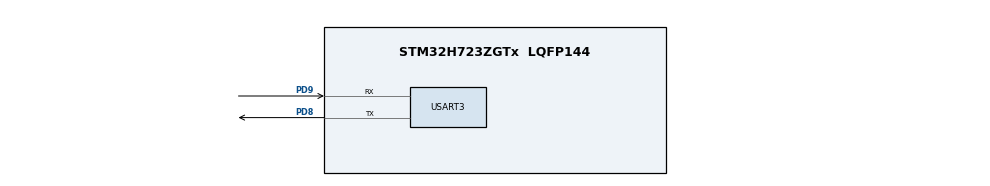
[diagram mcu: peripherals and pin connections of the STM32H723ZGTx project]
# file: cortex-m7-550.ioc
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Mcu.Family=STM32H7
VP_STMicroelectronics.X-CUBE-AI_VS_ArtificialOoIntelligenceJjXAaCUBEAaAI_6.0.0.Mode=ArtificialOoIntelligenceJjXAaCUBEAaAI
RCC.CortexFreq_Value=550000000
STMicroelectronics.X-CUBE-AI.6.0.0.MaximumSizeOfInputLayer=AI_NETWORK_IN_1_SIZE_BYTES
RCC.HPRE=RCC_HCLK_DIV2
RCC.PLLFRACN=3072
PA13(JTMS/SWDIO).Signal=DEBUG_JTMS-SWDIO
RCC.PLL2FRACN=0
STMicroelectronics.X-CUBE-AI.6.0.0.StackSize=0x1000
PD8.GPIO_PuPd=GPIO_PULLUP
PD9.Mode=Asynchronous
RCC.SYSCLKSource=RCC_SYSCLKSOURCE_PLLCLK
ProjectManager.StackSize=0x1000
PA13(JTMS/SWDIO).Mode=Trace_Asynchronous_SW
USART3.VirtualMode-Asynchronous=VM_ASYNC
STMicroelectronics.X-CUBE-AI.6.0.0.ModelType-336dc0c4d0ba22692615627b5872e3af75208939208f4fb2798e3d2edae12cc2=Saved model
RCC.HCLKFreq_Value=275000000
PD8.Signal=USART3_TX
STMicroelectronics.X-CUBE-AI.6.0.0.ModelStructureFile-336dc0c4d0ba22692615627b5872e3af75208939208f4fb2798e3d2edae12cc2=/Users/dominikpiorkowski/Desktop/drive/projekty/ML models/predict house price/predict_house_price.h5
RCC.DIVM1=4
STMicroelectronics.X-CUBE-AI.6.0.0.ModelMacc-336dc0c4d0ba22692615627b5872e3af75208939208f4fb2798e3d2edae12cc2=6771
STMicroelectronics.X-CUBE-AI.6.0.0.XAaCUBEAaAICcArtificialOoIntelligenceJjCore=true
PB3(JTDO/TRACESWO).Signal=DEBUG_JTDO-SWO
RCC.APB3Freq_Value=137500000
Mcu.Package=LQFP144
RCC.PLL3FRACN=0
RCC.D1PPRE=RCC_APB3_DIV2
PB3(JTDO/TRACESWO).Mode=Trace_Asynchronous_SW
STMicroelectronics.X-CUBE-AI.6.0.0.LatestDirectoryUsed-336dc0c4d0ba22692615627b5872e3af75208939208f4fb2798e3d2edae12cc2=/Users/dominikpiorkowski/Desktop/drive/projekty/ML models/predict house price
STMicroelectronics.X-CUBE-AI.6.0.0.ModelCompression-336dc0c4d0ba22692615627b5872e3af75208939208f4fb2798e3d2edae12cc2=1
RCC.APB4Freq_Value=137500000
TIM16.AutoReloadPreload=TIM_AUTORELOAD_PRELOAD_ENABLE
TIM16.Prescaler=9000-1
PD9.GPIO_PuPd=GPIO_PULLUP
STMicroelectronics.X-CUBE-AI.6.0.0.ModelKind-336dc0c4d0ba22692615627b5872e3af75208939208f4fb2798e3d2edae12cc2=KERAS
CORTEX_M7.CPU_ICache=Enabled
STMicroelectronics.X-CUBE-AI.6.0.0.MaximumSizeOfOutputLayer=AI_NETWORK_OUT_1_SIZE_BYTES
RCC.D2PPRE2=RCC_APB2_DIV2
RCC.D2PPRE1=RCC_APB1_DIV2
PD9.Signal=USART3_RX
VP_TIM16_VS_ClockSourceINT.Mode=Enable_Timer
RCC.DIVP1=1
NVIC.TIM16_IRQn=true\:0\:0\:false\:false\:true\:true\:true
STMicroelectronics.X-CUBE-AI.6.0.0.ModelHashList=336dc0c4d0ba22692615627b5872e3af75208939208f4fb2798e3d2edae12cc2
ProjectManager.TargetToolchain=STM32CubeIDE
STMicroelectronics.X-CUBE-AI.6.0.0.InternalRamActivationBufferMaxSize=AI_NETWORK_DATA_ACTIVATIONS_SIZE
RCC.DIVN1=34
STMicroelectronics.X-CUBE-AI.6.0.0.WorkingBufferStartAddrList=0xFFFFFFFF
STMicroelectronics.X-CUBE-AI.6.0.0.ModelNameList=network
RCC.USBFreq_Value=275000000
STMicroelectronics.X-CUBE-AI.6.0.0.MaximumNumberOfOutputLayer=1
PD8.Mode=Asynchronous
board=custom
TIM16.Period=10000-1
RCC.APB2Freq_Value=137500000
RCC.ADCFreq_Value=129000000
STMicroelectronics.X-CUBE-AI.6.0.0.ModelName-336dc0c4d0ba22692615627b5872e3af75208939208f4fb2798e3d2edae12cc2=network
STMicroelectronics.X-CUBE-AI.6.0.0.ModelRamOccupation-336dc0c4d0ba22692615627b5872e3af75208939208f4fb2798e3d2edae12cc2=384
PA14(JTCK/SWCLK).Mode=Trace_Asynchronous_SW
Mcu.Name=STM32H723ZGTx
RCC.SYSCLKFreq_VALUE=550000000
STMicroelectronics.X-CUBE-AI.6.0.0.ModelActualCompression-336dc0c4d0ba22692615627b5872e3af75208939208f4fb2798e3d2edae12cc2=0.0
STMicroelectronics.X-CUBE-AI.6.0.0.MaximumNumberOfInputLayer=1
ProjectManager.HeapSize=0x200
STMicroelectronics.X-CUBE-AI.6.0.0.HeapSize=0x200
NVIC.PriorityGroup=NVIC_PRIORITYGROUP_4
RCC.D3PPRE=RCC_APB4_DIV2
PA14(JTCK/SWCLK).Signal=DEBUG_JTCK-SWCLK
CORTEX_M7.CPU_DCache=Enabled
RCC.APB1Freq_Value=137500000
VP_CRC_VS_CRC.Mode=CRC_Activate
STMicroelectronics.X-CUBE-AI.6.0.0.ActivationBufferSizeList=384
STMicroelectronics.X-CUBE-AI.6.0.0.ModelFlashOccupation-336dc0c4d0ba22692615627b5872e3af75208939208f4fb2798e3d2edae12cc2=26136

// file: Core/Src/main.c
/* USER CODE BEGIN Header */
/**
  ******************************************************************************
  * @file           : main.c
  * @brief          : Main program body
  ******************************************************************************
  * @attention
  *
  * Copyright (c)	2021 STMicroelectronics,
  * 				2021 Dominik Piórkowski.
  *
  * All rights reserved.
  *
  * This software component is licensed by ST under BSD 3-Clause license,
  * the "License"; You may not use this file except in compliance with the
  * License. You may obtain a copy of the License at:
  *                        opensource.org/licenses/BSD-3-Clause
  *
  ******************************************************************************
  */

/*
 * main.c
 *
 *  Created on: 3 May 2021
 *      Author: dominikpiorkowski
 */

/* USER CODE END Header */
#include "main.h"
#include "crc.h"
#include "tim.h"
#include "usart.h"
#include "gpio.h"

/* USER CODE BEGIN Includes */
#include <stdio.h>

#include "ai_platform.h"
#include "network.h"
#include "network_data.h"
#include "test_input.h"
/* USER CODE END Includes */

/* USER CODE BEGIN PV */
char buf[50];
int buf_len = 0;
ai_handle network;

uint32_t timer_counter = 0;
uint32_t timestamp = 0;

float aiOutData[3][AI_NETWORK_OUT_1_SIZE];
uint8_t activations[AI_NETWORK_DATA_ACTIVATIONS_SIZE];
/* USER CODE END PV */

void SystemClock_Config(void);
/* USER CODE BEGIN PFP */
static void AI_Init(ai_handle w_addr, ai_handle act_addr);
static void AI_Run(float *pIn, float *pOut);
/* USER CODE END PFP */

int main(void)
{

  /* Enable I-Cache---------------------------------------------------------*/
  SCB_EnableICache();

  /* Enable D-Cache---------------------------------------------------------*/
  SCB_EnableDCache();

  /* MCU Configuration--------------------------------------------------------*/

  /* Reset of all peripherals, Initializes the Flash interface and the Systick. */
  HAL_Init();

  /* Configure the system clock */
  SystemClock_Config();

  /* Initialize all configured peripherals */
  MX_GPIO_Init();
  MX_CRC_Init();
  MX_TIM16_Init();
  MX_USART3_UART_Init();
  /* USER CODE BEGIN 2 */
  AI_Init(ai_network_data_weights_get(), activations);

  //  Start timer/counter
  HAL_TIM_Base_Start_IT(&htim16);
  /* USER CODE END 2 */

  /* Infinite loop */
  /* USER CODE BEGIN WHILE */
  while (1)
  {
	  buf_len = sprintf(buf, "M7-550 Running HPP inference \n");
	  HAL_UART_Transmit(&huart3, (uint8_t *)buf, buf_len, 100);

	  timestamp = htim16.Instance->CNT;

	  //	  predicted price should be = 207305
	  AI_Run(aiInDataHouse0, aiOutData[0]);

	  //	  predicted price should be = 408886
	  AI_Run(aiInDataHouse1, aiOutData[1]);

	  //	  predicted price should be = 392844
	  AI_Run(aiInDataHouse2, aiOutData[2]);

	  buf_len = sprintf(buf, "Inference duration: (%lu s) + %lu*0.01ms \n", timer_counter, (htim16.Instance->CNT - timestamp));
	  HAL_UART_Transmit(&huart3, (uint8_t *)buf, buf_len, 100);

	  buf_len = sprintf(buf, "1 predicted price: %f \n", aiOutData[0][0]);
	  HAL_UART_Transmit(&huart3, (uint8_t *)buf, buf_len, 100);
	  buf_len = sprintf(buf, "2 predicted price: %f \n", aiOutData[1][0]);
	  HAL_UART_Transmit(&huart3, (uint8_t *)buf, buf_len, 100);
	  buf_len = sprintf(buf, "3 predicted price: %f \n", aiOutData[2][0]);
	  HAL_UART_Transmit(&huart3, (uint8_t *)buf, buf_len, 100);
    /* USER CODE END WHILE */

  }
}

void SystemClock_Config(void)
{
  RCC_OscInitTypeDef RCC_OscInitStruct = {0};
  RCC_ClkInitTypeDef RCC_ClkInitStruct = {0};

  /** Supply configuration update enable
  */
  HAL_PWREx_ConfigSupply(PWR_LDO_SUPPLY);
  /** Configure the main internal regulator output voltage
  */
  __HAL_PWR_VOLTAGESCALING_CONFIG(PWR_REGULATOR_VOLTAGE_SCALE0);

  while(!__HAL_PWR_GET_FLAG(PWR_FLAG_VOSRDY)) {}
  /** Initializes the RCC Oscillators according to the specified parameters
  * in the RCC_OscInitTypeDef structure.
  */
  RCC_OscInitStruct.OscillatorType = RCC_OSCILLATORTYPE_HSI;
  RCC_OscInitStruct.HSIState = RCC_HSI_DIV1;
  RCC_OscInitStruct.HSICalibrationValue = RCC_HSICALIBRATION_DEFAULT;
  RCC_OscInitStruct.PLL.PLLState = RCC_PLL_ON;
  RCC_OscInitStruct.PLL.PLLSource = RCC_PLLSOURCE_HSI;
  RCC_OscInitStruct.PLL.PLLM = 4;
  RCC_OscInitStruct.PLL.PLLN = 34;
  RCC_OscInitStruct.PLL.PLLP = 1;
  RCC_OscInitStruct.PLL.PLLQ = 2;
  RCC_OscInitStruct.PLL.PLLR = 2;
  RCC_OscInitStruct.PLL.PLLRGE = RCC_PLL1VCIRANGE_3;
  RCC_OscInitStruct.PLL.PLLVCOSEL = RCC_PLL1VCOWIDE;
  RCC_OscInitStruct.PLL.PLLFRACN = 3072;
  if (HAL_RCC_OscConfig(&RCC_OscInitStruct) != HAL_OK)
  {
    Error_Handler();
  }
  /** Initializes the CPU, AHB and APB buses clocks
  */
  RCC_ClkInitStruct.ClockType = RCC_CLOCKTYPE_HCLK|RCC_CLOCKTYPE_SYSCLK
                              |RCC_CLOCKTYPE_PCLK1|RCC_CLOCKTYPE_PCLK2
                              |RCC_CLOCKTYPE_D3PCLK1|RCC_CLOCKTYPE_D1PCLK1;
  RCC_ClkInitStruct.SYSCLKSource = RCC_SYSCLKSOURCE_PLLCLK;
  RCC_ClkInitStruct.SYSCLKDivider = RCC_SYSCLK_DIV1;
  RCC_ClkInitStruct.AHBCLKDivider = RCC_HCLK_DIV2;
  RCC_ClkInitStruct.APB3CLKDivider = RCC_APB3_DIV2;
  RCC_ClkInitStruct.APB1CLKDivider = RCC_APB1_DIV2;
  RCC_ClkInitStruct.APB2CLKDivider = RCC_APB2_DIV2;
  RCC_ClkInitStruct.APB4CLKDivider = RCC_APB4_DIV2;

  if (HAL_RCC_ClockConfig(&RCC_ClkInitStruct, FLASH_LATENCY_3) != HAL_OK)
  {
    Error_Handler();
  }
}

/* USER CODE BEGIN 4 */
void HAL_TIM_PeriodElapsedCallback(TIM_HandleTypeDef *htim)
{
	if (htim == &htim16 )
	{
		++timer_counter;
	}
}

static void AI_Init(ai_handle w_addr, ai_handle act_addr)
{
	ai_error err;

	/* 1 - Create an instance of the model */
	err = ai_network_create(&network, AI_NETWORK_DATA_CONFIG);
	if (err.type != AI_ERROR_NONE) {
		printf("ai_network_create error - type=%d code=%d\r\n", err.type, err.code);
		Error_Handler();
	}

	/* 2 - Initialize the instance */
	const ai_network_params params = {
			AI_NETWORK_DATA_WEIGHTS(w_addr),
			AI_NETWORK_DATA_ACTIVATIONS(act_addr)
	};

	if (!ai_network_init(network, &params))
	{
		err = ai_network_get_error(network);
		printf("ai_network_init error - type=%d code=%d\r\n", err.type, err.code);
		Error_Handler();
	}
}
static void AI_Run(float *pIn, float *pOut)
{
	ai_i32 batch;
	ai_error err;

	/* 1 - Create the AI buffer IO handlers with the default definition */
	ai_buffer ai_input[AI_NETWORK_IN_NUM] = AI_NETWORK_IN;
	ai_buffer ai_output[AI_NETWORK_OUT_NUM] = AI_NETWORK_OUT;

	/* 2 - Update IO handlers with the data payload */
	ai_input[0].n_batches = 1;
	ai_input[0].data = AI_HANDLE_PTR(pIn);
	ai_output[0].n_batches = 1;
	ai_output[0].data = AI_HANDLE_PTR(pOut);

	batch = ai_network_run(network, ai_input, ai_output);
	if (batch != 1)
	{
		err = ai_network_get_error(network);
		buf_len = sprintf(buf, "AI ai_network_run error - type=%d code=%d \n", err.type, err.code);
		HAL_UART_Transmit(&huart3, (uint8_t *)buf, buf_len, 100);
		Error_Handler();
	}
}
/* USER CODE END 4 */

void Error_Handler(void)
{
  __disable_irq();
  while (1)
  {
  }
}

/************************ (C) COPYRIGHT STMicroelectronics *****END OF FILE****/
